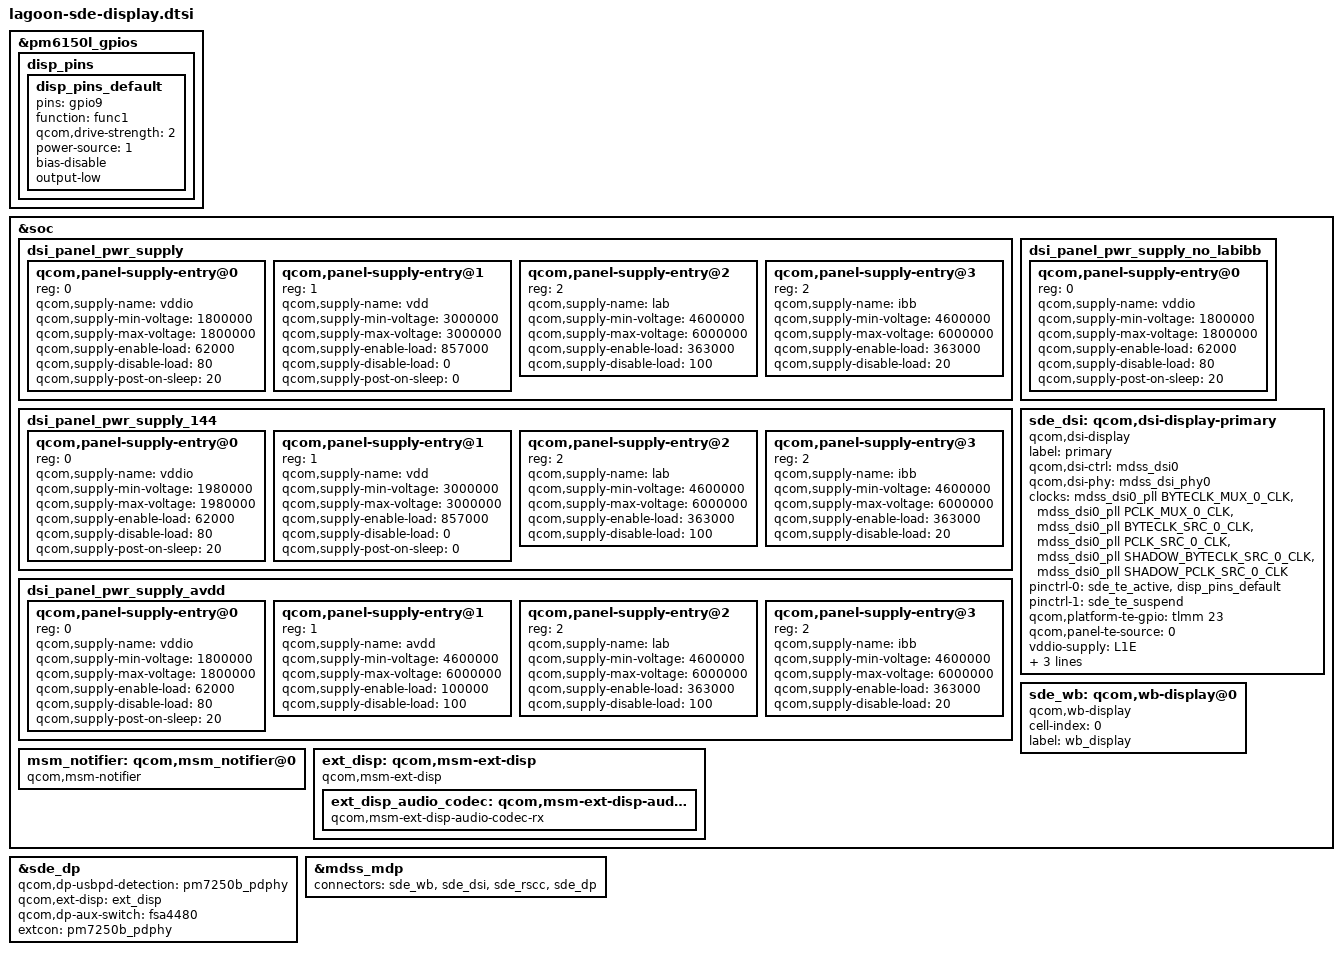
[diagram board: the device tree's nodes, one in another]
#include <dt-bindings/clock/mdss-10nm-pll-clk.h>

&pm6150l_gpios {
	disp_pins {
		disp_pins_default: disp_pins_default {
			pins = "gpio9";
			function = "func1";
			qcom,drive-strength = <2>;
			power-source = <1>;
			bias-disable;
			output-low;
		};
	};
};

&soc {
	dsi_panel_pwr_supply: dsi_panel_pwr_supply {
		#address-cells = <1>;
		#size-cells = <0>;

		qcom,panel-supply-entry@0 {
			reg = <0>;
			qcom,supply-name = "vddio";
			qcom,supply-min-voltage = <1800000>;
			qcom,supply-max-voltage = <1800000>;
			qcom,supply-enable-load = <62000>;
			qcom,supply-disable-load = <80>;
			qcom,supply-post-on-sleep = <20>;
		};

		qcom,panel-supply-entry@1 {
			reg = <1>;
			qcom,supply-name = "vdd";
			qcom,supply-min-voltage = <3000000>;
			qcom,supply-max-voltage = <3000000>;
			qcom,supply-enable-load = <857000>;
			qcom,supply-disable-load = <0>;
			qcom,supply-post-on-sleep = <0>;
		};

		qcom,panel-supply-entry@2 {
			reg = <2>;
			qcom,supply-name = "lab";
			qcom,supply-min-voltage = <4600000>;
			qcom,supply-max-voltage = <6000000>;
			qcom,supply-enable-load = <363000>;
			qcom,supply-disable-load = <100>;
		};

		qcom,panel-supply-entry@3 {
			reg = <2>;
			qcom,supply-name = "ibb";
			qcom,supply-min-voltage = <4600000>;
			qcom,supply-max-voltage = <6000000>;
			qcom,supply-enable-load = <363000>;
			qcom,supply-disable-load = <20>;
		};
	};

	dsi_panel_pwr_supply_144: dsi_panel_pwr_supply_144 {
		#address-cells = <1>;
		#size-cells = <0>;

		qcom,panel-supply-entry@0 {
			reg = <0>;
			qcom,supply-name = "vddio";
			qcom,supply-min-voltage = <1980000>;
			qcom,supply-max-voltage = <1980000>;
			qcom,supply-enable-load = <62000>;
			qcom,supply-disable-load = <80>;
			qcom,supply-post-on-sleep = <20>;
		};

		qcom,panel-supply-entry@1 {
			reg = <1>;
			qcom,supply-name = "vdd";
			qcom,supply-min-voltage = <3000000>;
			qcom,supply-max-voltage = <3000000>;
			qcom,supply-enable-load = <857000>;
			qcom,supply-disable-load = <0>;
			qcom,supply-post-on-sleep = <0>;
		};

		qcom,panel-supply-entry@2 {
			reg = <2>;
			qcom,supply-name = "lab";
			qcom,supply-min-voltage = <4600000>;
			qcom,supply-max-voltage = <6000000>;
			qcom,supply-enable-load = <363000>;
			qcom,supply-disable-load = <100>;
		};

		qcom,panel-supply-entry@3 {
			reg = <2>;
			qcom,supply-name = "ibb";
			qcom,supply-min-voltage = <4600000>;
			qcom,supply-max-voltage = <6000000>;
			qcom,supply-enable-load = <363000>;
			qcom,supply-disable-load = <20>;
		};
	};

	dsi_panel_pwr_supply_avdd: dsi_panel_pwr_supply_avdd {
		#address-cells = <1>;
		#size-cells = <0>;

		qcom,panel-supply-entry@0 {
			reg = <0>;
			qcom,supply-name = "vddio";
			qcom,supply-min-voltage = <1800000>;
			qcom,supply-max-voltage = <1800000>;
			qcom,supply-enable-load = <62000>;
			qcom,supply-disable-load = <80>;
			qcom,supply-post-on-sleep = <20>;
		};

		qcom,panel-supply-entry@1 {
			reg = <1>;
			qcom,supply-name = "avdd";
			qcom,supply-min-voltage = <4600000>;
			qcom,supply-max-voltage = <6000000>;
			qcom,supply-enable-load = <100000>;
			qcom,supply-disable-load = <100>;
		};

		qcom,panel-supply-entry@2 {
			reg = <2>;
			qcom,supply-name = "lab";
			qcom,supply-min-voltage = <4600000>;
			qcom,supply-max-voltage = <6000000>;
			qcom,supply-enable-load = <363000>;
			qcom,supply-disable-load = <100>;
		};

		qcom,panel-supply-entry@3 {
			reg = <2>;
			qcom,supply-name = "ibb";
			qcom,supply-min-voltage = <4600000>;
			qcom,supply-max-voltage = <6000000>;
			qcom,supply-enable-load = <363000>;
			qcom,supply-disable-load = <20>;
		};
	};

	dsi_panel_pwr_supply_no_labibb: dsi_panel_pwr_supply_no_labibb {
		#address-cells = <1>;
		#size-cells = <0>;

		qcom,panel-supply-entry@0 {
			reg = <0>;
			qcom,supply-name = "vddio";
			qcom,supply-min-voltage = <1800000>;
			qcom,supply-max-voltage = <1800000>;
			qcom,supply-enable-load = <62000>;
			qcom,supply-disable-load = <80>;
			qcom,supply-post-on-sleep = <20>;
		};
	};

	sde_dsi: qcom,dsi-display-primary {
		compatible = "qcom,dsi-display";
		label = "primary";

		qcom,dsi-ctrl = <&mdss_dsi0>;
		qcom,dsi-phy = <&mdss_dsi_phy0>;

		clocks = <&mdss_dsi0_pll BYTECLK_MUX_0_CLK>,
			 <&mdss_dsi0_pll PCLK_MUX_0_CLK>,
			 <&mdss_dsi0_pll BYTECLK_SRC_0_CLK>,
			 <&mdss_dsi0_pll PCLK_SRC_0_CLK>,
			 <&mdss_dsi0_pll SHADOW_BYTECLK_SRC_0_CLK>,
			 <&mdss_dsi0_pll SHADOW_PCLK_SRC_0_CLK>;
		clock-names = "mux_byte_clk0", "mux_pixel_clk0",
				"src_byte_clk0", "src_pixel_clk0",
				"shadow_byte_clk0", "shadow_pixel_clk0";

		pinctrl-names = "panel_active", "panel_suspend";
		pinctrl-0 = <&sde_te_active &disp_pins_default>;
		pinctrl-1 = <&sde_te_suspend>;

		qcom,platform-te-gpio = <&tlmm 23 0>;
		qcom,panel-te-source = <0>;

		vddio-supply = <&L1E>;
		//vdd-supply = <&L8A>;
		lab-supply = <&ab_vreg>;
		ibb-supply = <&ibb_vreg>;

		qcom,mdp = <&mdss_mdp>;
	};

	sde_wb: qcom,wb-display@0 {
		compatible = "qcom,wb-display";
		cell-index = <0>;
		label = "wb_display";
	};

	msm_notifier: qcom,msm_notifier@0 {
		compatible = "qcom,msm-notifier";
	};

	ext_disp: qcom,msm-ext-disp {
		compatible = "qcom,msm-ext-disp";

		ext_disp_audio_codec: qcom,msm-ext-disp-audio-codec-rx {
			compatible = "qcom,msm-ext-disp-audio-codec-rx";
		};
	};

};

&sde_dp {
	qcom,dp-usbpd-detection = <&pm7250b_pdphy>;
	qcom,ext-disp = <&ext_disp>;
	qcom,dp-aux-switch = <&fsa4480>;

	extcon = <&pm7250b_pdphy>;
};

&mdss_mdp {
	connectors = <&sde_wb &sde_dsi &sde_rscc &sde_dp>;
};
